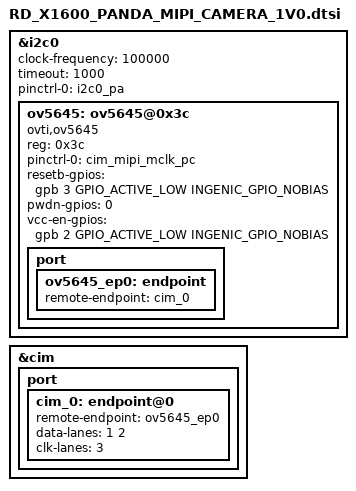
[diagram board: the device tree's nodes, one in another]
&i2c0 {
	status = "okay";
	clock-frequency = <100000>;
	timeout = <1000>;
	pinctrl-names = "default";
	pinctrl-0 = <&i2c0_pa>;

	ov5645:ov5645@0x3c {
		status = "okay";
		compatible = "ovti,ov5645";
		reg = <0x3c>;
		pinctrl-names = "default";
		pinctrl-0 = <&cim_mipi_mclk_pc>;

		resetb-gpios = <&gpb 3 GPIO_ACTIVE_LOW INGENIC_GPIO_NOBIAS>;
		pwdn-gpios = <0>;
		vcc-en-gpios = <&gpb 2 GPIO_ACTIVE_LOW INGENIC_GPIO_NOBIAS>;

		port {
			ov5645_ep0:endpoint {
				remote-endpoint = <&cim_0>;
			};
		};
	};
};

&cim {
	status = "okay";
	port {
		cim_0: endpoint@0 {
			remote-endpoint = <&ov5645_ep0>;
			data-lanes = <1 2>;
			clk-lanes = <3>;
		};
	};
};

